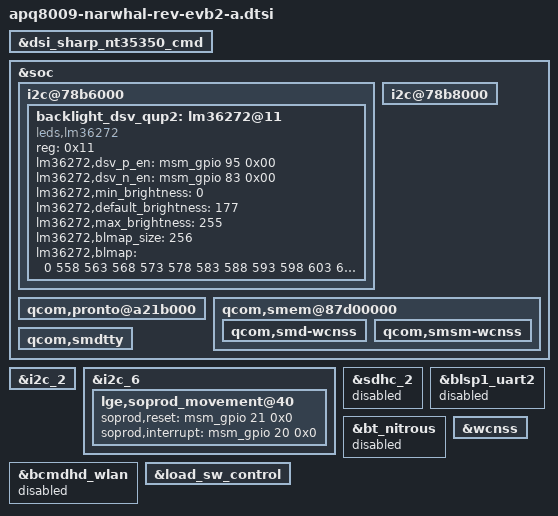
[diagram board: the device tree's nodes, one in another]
/* Copyright (c) 2017, LGE Inc. All rights reserved.
 *
 * This program is free software; you can redistribute it and/or modify
 * it under the terms of the GNU General Public License version 2 and
 * only version 2 as published by the Free Software Foundation.
 *
 * This program is distributed in the hope that it will be useful,
 * but WITHOUT ANY WARRANTY; without even the implied warranty of
 * MERCHANTABILITY or FITNESS FOR A PARTICULAR PURPOSE.  See the
 * GNU General Public License for more details.
 */

#include "apq8009-narwhal.dtsi"

&dsi_sharp_nt35350_cmd {
	/delete-property/ qcom,mdss-dsi-te-pin-select;
	/delete-property/ qcom,mdss-dsi-te-check-enable;
	/delete-property/ qcom,mdss-dsi-te-using-te-pin;
	/delete-property/ qcom,esd-check-enabled;
	/delete-property/ qcom,mdss-dsi-panel-status-check-mode;
};

&soc {
	i2c@78b6000 { /* BLSP1 QUP2 */
		backlight_dsv_qup2: lm36272@11 {
			compatible = "leds,lm36272";
			status = "okay";
			reg = <0x11>;
			lm36272,dsv_p_en = <&msm_gpio 95 0x00>;
			lm36272,dsv_n_en = <&msm_gpio 83 0x00>;
			lm36272,min_brightness = <0>;
			lm36272,default_brightness = <177>;
			lm36272,max_brightness = <255>;
			lm36272,blmap_size = <256>;
			lm36272,blmap = <
				0 558 563 568 573 578 583 588 593 598               /* 0-9 */
				603 608 613 618 623 628 633 638 643 648             /* 10-19 */
				653 658 663 668 673 678 683 688 693 698             /* 20-29 */
				703 708 713 718 723 728 733 738 743 748             /* 30-39 */
				753 758 763 768 773 778 783 788 793 798             /* 40-49 */
				803 808 813 818 823 828 833 838 843 848             /* 50-59 */
				853 858 863 868 873 878 883 888 893 898             /* 60-69 */
				903 908 913 918 923 928 933 938 943 948             /* 70-79 */
				953 958 963 968 973 978 983 988 993 998             /* 80-89 */
				1003 1008 1013 1018 1023 1028 1033 1038 1043 1048   /* 90-99 */
				1053 1058 1063 1068 1073 1078 1083 1088 1093 1098   /* 100-109 */
				1103 1108 1113 1118 1123 1128 1133 1138 1143 1148   /* 110-119 */
				1153 1158 1163 1168 1173 1178 1183 1188 1193 1198   /* 120-129 */
				1203 1208 1213 1218 1223 1228 1233 1238 1243 1248   /* 130-139 */
				1253 1258 1263 1268 1273 1278 1283 1288 1293 1298   /* 140-149 */
				1303 1308 1313 1318 1323 1328 1333 1338 1343 1348   /* 150-159 */
				1353 1358 1363 1368 1373 1378 1383 1388 1393 1398   /* 160-169 */
				1403 1408 1413 1418 1423 1428 1433 1438 1443 1448   /* 170-179 */
				1453 1458 1463 1468 1473 1478 1483 1488 1493 1498   /* 180-189 */
				1503 1508 1513 1518 1523 1528 1533 1538 1543 1548   /* 190-199 */
				1553 1558 1563 1568 1573 1578 1583 1588 1593 1598   /* 200-209 */
				1603 1608 1613 1618 1623 1628 1633 1638 1643 1648   /* 210-219 */
				1653 1658 1663 1668 1673 1678 1683 1688 1693 1698   /* 220-229 */
				1703 1708 1713 1718 1723 1728 1733 1738 1743 1748   /* 230-239 */
				1753 1758 1763 1768 1773 1778 1783 1788 1793 1798   /* 240-249 */
				1803 1808 1813 1818 1823 1863                       /* 250-255 */
			>;
		};
	};

	i2c@78b8000 { /* BLSP1 QUP4 */
		/delete-node/ lm36272@11;
	};

	/* wcnss */
	qcom,pronto@a21b000 {
		status = "ok";
	};
	qcom,smem@87d00000 {
		qcom,smd-wcnss {
			status = "ok";
		};
		qcom,smsm-wcnss {
			status = "ok";
		};
	};
	qcom,smdtty {
		status = "ok";
	};
};

&i2c_2 {
	status = "ok";
};

&i2c_6 {
	lge,soprod_movement@40 {
		soprod,reset = <&msm_gpio 21 0x0>;
		soprod,interrupt = <&msm_gpio 20 0x0>;
	};
};

&sdhc_2 {
	status = "disabled";
};

&blsp1_uart2 {
	status = "disabled";
};

&bt_nitrous {
	status = "disabled";
};

&wcnss {
	status = "ok";
};

&bcmdhd_wlan {
	status = "disabled";
};

&load_sw_control {
	status = "ok";
};
